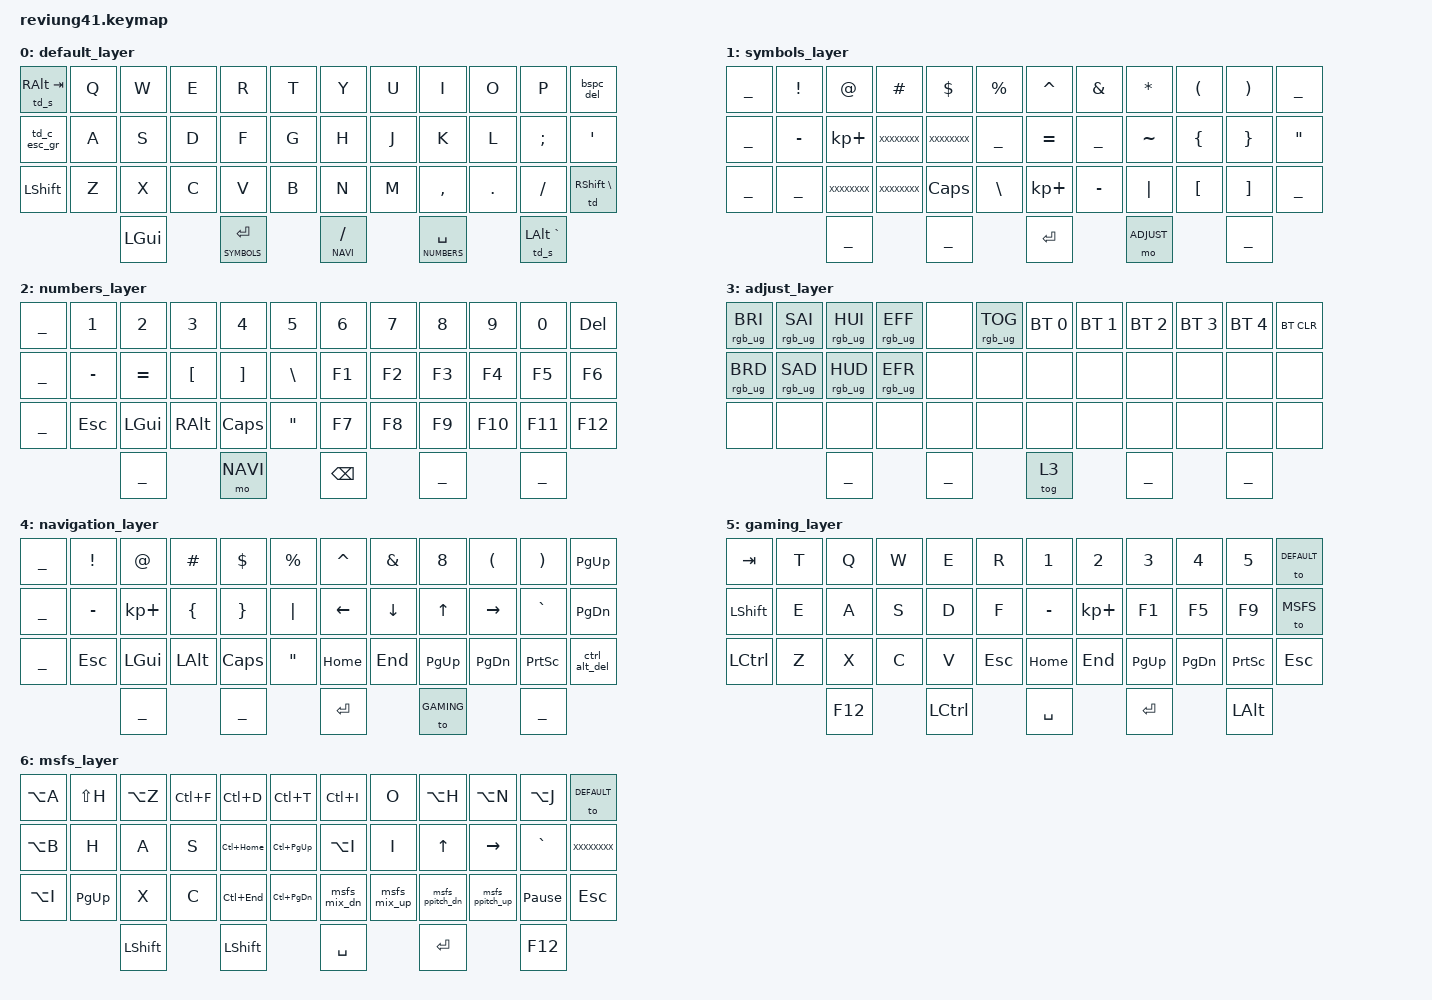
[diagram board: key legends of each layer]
/*
 * Copyright (c) 2020 The ZMK Contributors
 *
 * SPDX-License-Identifier: MIT
 */
#define REVIUNG41

#include <behaviors.dtsi>
#include <dt-bindings/zmk/keys.h>
#include <dt-bindings/zmk/bt.h>
#include <dt-bindings/zmk/rgb.h>
#include "../layer8/config.dtsi"
#include "../layer8/tap_dances.dtsi"
#include "../layer8/mod_morphs.dtsi"
#include "../layer8/macros.dtsi"

/ {
        keymap {
                compatible = "zmk,keymap";

                default_layer {
                        bindings = <
   &td_s RALT TAB &kp Q &kp W &kp E &kp R &kp T   &kp Y &kp U  &kp I     &kp O   &kp P    &bspc_del
   &td_c_esc_gr   &kp A &kp S &kp D &kp F &kp G   &kp H &kp J  &kp K     &kp L   &kp SEMI &kp SQT
   &kp LSHFT      &kp Z &kp X &kp C &kp V &kp B   &kp N &kp M  &kp COMMA &kp DOT &kp FSLH &td RSHFT BACKSLASH
                        &kp LGUI  &lt SYMBOLS RET &lt NAVI FSLH &lt NUMBERS SPACE  &td_s LALT GRAVE
                        >;
                };

                symbols_layer {
                        bindings = <
   ________ &kp EXCL  &kp AT      &kp HASH &kp DLLR &kp PRCNT         &kp CARET    &kp AMPS        &kp STAR  &kp LPAR  &kp RPAR  ________
   ________ &kp MINUS &kp KP_PLUS XXXXXXXX XXXXXXXX &kp UNDER         &kp EQUAL    &kp UNDERSCORE  &kp TILDE &kp LBRC  &kp RBRC  &kp DQT
   ________ &kp UNDER XXXXXXXX    XXXXXXXX &kp CLCK  &kp BACKSLASH    &kp KP_PLUS  &kp MINUS       &kp PIPE  &kp LBKT  &kp RBKT ________
                                 ________      ________       &kp RET        &mo ADJUST       ________
                        >;
                };

                numbers_layer {
                        bindings = <
   ________ &kp N1    &kp N2    &kp N3    &kp N4    &kp N5        &kp N6    &kp N7    &kp N8    &kp N9    &kp N0    &kp DEL
   ________ &kp MINUS &kp EQUAL &kp LBKT  &kp RBKT  &kp BSLH      &kp F1    &kp F2    &kp F3    &kp F4    &kp F5    &kp F6
   ________ &kp ESC   &kp LGUI  &kp RALT  &kp CLCK  &kp DQT       &kp F7    &kp F8    &kp F9    &kp F10   &kp F11   &kp F12
                                ________      &mo NAVI       &kp BSPC        ________      ________
                        >;
                };

               adjust_layer {
                        bindings = <
   &rgb_ug RGB_BRI &rgb_ug RGB_SAI &rgb_ug RGB_HUI &rgb_ug RGB_EFF &none &rgb_ug RGB_TOG    &bt BT_SEL 0 &bt BT_SEL 1 &bt BT_SEL 2 &bt BT_SEL 3 &bt BT_SEL 4 &bt BT_CLR
   &rgb_ug RGB_BRD &rgb_ug RGB_SAD &rgb_ug RGB_HUD &rgb_ug RGB_EFR &none &none              &none        &none        &none        &none        &none        &none
   &none           &none           &none           &none           &none &none              &none       &none        &none        &none        &none        &none
                                                             ________      ________       &tog 3        ________      ________
                        >;
                };

                navigation_layer {
                        bindings = <
   ________ &kp EXCL  &kp AT      &kp HASH &kp DLLR &kp PRCNT      &kp CARET &kp AMPS &kp N8    &kp LPAR  &kp RPAR  &kp PG_UP
   ________ &kp MINUS &kp KP_PLUS &kp LBRC &kp RBRC &kp PIPE       &kp LEFT  &kp DOWN &kp UP    &kp RIGHT &kp GRAVE &kp PG_DN
   ________ &kp ESC   &kp LGUI    &kp LALT &kp CLCK &kp DQT        &kp HOME  &kp END  &kp PG_UP &kp PG_DN &kp PSCRN &ctrl_alt_del
                                 ________      ________       &kp RET        &to GAMING       ________
                        >;
                };

                gaming_layer {
                        bindings = <
   &kp TAB   &kp T &kp Q   &kp W    &kp E &kp R          &kp N1    &kp N2      &kp N3    &kp N4    &kp N5    &to DEFAULT
   &kp LSHFT &kp E &kp A   &kp S    &kp D &kp F          &kp MINUS &kp KP_PLUS &kp F1    &kp F5    &kp F9    &to MSFS
   &kp LCTRL &kp Z &kp X   &kp C    &kp V &kp ESC        &kp HOME  &kp END     &kp PG_UP &kp PG_DN &kp PSCRN &kp ESC
                                 &kp F12      &kp LCTRL       &kp SPACE        &kp RET      &kp LALT
                        >;
                };

                msfs_layer {
                        bindings = <
   &kp LA(A) &kp LS(H)  &kp LA(Z)  &kp LC(F)  &kp LC(D) &kp LC(T)           &kp LC(I) &kp O &kp LA(H)    &kp LA(N)  &kp LA(J)  &to DEFAULT
   &kp LA(B) &kp H      &kp A      &kp S      &kp LC(HOME)     &kp LC(PG_UP)       &kp LA(I)  &kp I &kp UP    &kp RIGHT &kp GRAVE XXXXXXXX
   &kp LA(I) &kp PG_UP  &kp X      &kp C      &kp LC(END)     &kp LC(PG_DN)       &msfs_mix_dn  &msfs_mix_up &msfs_ppitch_dn &msfs_ppitch_up &kp PAUSE_BREAK &kp ESC
                                 &kp LSHFT      &kp LSHFT       &kp SPACE        &kp RET      &kp F12
                        >;
                };
        };
};
